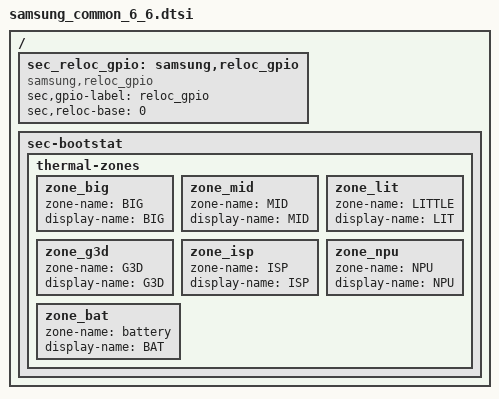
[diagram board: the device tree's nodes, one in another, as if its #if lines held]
/ {
	fragment@samsung_common {
		target-path = "/";
		__overlay__ {
#if defined(CONFIG_SEC_FACTORY)
			sec_reloc_gpio: samsung,reloc_gpio {
				compatible = "samsung,reloc_gpio";
				status = "okay";
				/* see, '/sys/kernel/debug/pinctrl' */
				sec,gpio-label = "reloc_gpio";
				sec,reloc-base = <0>;
			};
#endif
		};
	};
};

/* /home/dpi/qb5_8814/workspace/P4_1716/kernel/kmodule/samsung/slsi/common/6.6/dts/samsung_common_6_6._ap_slsi_s5e8855.dtsi */
/ {
	fragment@samsung_bootstat {
		target-path = "/";
		__overlay__ {
			sec-bootstat {
				thermal-zones {
					/* max number of thermal-zones is 10 */
					/* max length of display-name is 4 */
					zone_big {
						zone-name = "BIG";
						display-name = "BIG";
					};
					zone_mid {
						zone-name = "MID";
						display-name = "MID";
					};
					zone_lit {
						zone-name = "LITTLE";
						display-name = "LIT";
					};
					zone_g3d {
						zone-name = "G3D";
						display-name = "G3D";
					};
					zone_isp {
						zone-name = "ISP";
						display-name = "ISP";
					};
					zone_npu {
						zone-name = "NPU";
						display-name = "NPU";
					};
					zone_bat {
						zone-name = "battery";
						display-name = "BAT";
					};
				};
			};
		};
	};
};
